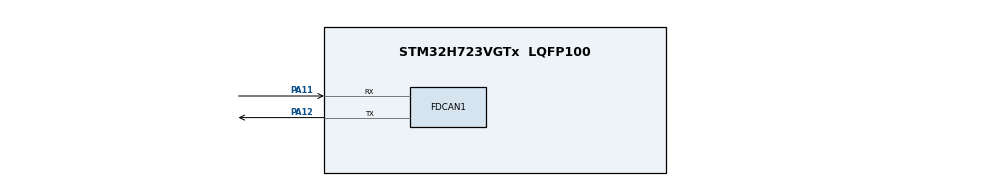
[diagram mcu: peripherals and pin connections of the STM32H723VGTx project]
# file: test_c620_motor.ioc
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CORTEX_M7.default_mode_Activation=1
FDCAN1.AutoRetransmission=ENABLE
FDCAN1.CalculateBaudRateNominal=1000000
FDCAN1.CalculateTimeBitNominal=1000
FDCAN1.CalculateTimeQuantumNominal=100.0
FDCAN1.DataPrescaler=10
FDCAN1.DataTimeSeg1=5
FDCAN1.DataTimeSeg2=4
FDCAN1.NominalPrescaler=10
FDCAN1.NominalTimeSeg1=5
FDCAN1.NominalTimeSeg2=4
FDCAN1.RxFifo1ElmtsNbr=16
FDCAN1.TxFifoQueueElmtsNbr=16
Mcu.Family=STM32H7
Mcu.Name=STM32H723VGTx
Mcu.Package=LQFP100
NVIC.FDCAN1_IT0_IRQn=true\:0\:0\:false\:false\:true\:true\:true\:true
NVIC.PriorityGroup=NVIC_PRIORITYGROUP_4
NVIC.TIM23_IRQn=true\:15\:0\:false\:false\:true\:false\:true\:true
NVIC.TimeBase=TIM23_IRQn
NVIC.TimeBaseIP=TIM23
PA11.Mode=FDCAN_Activate
PA11.Signal=FDCAN1_RX
PA12.Mode=FDCAN_Activate
PA12.Signal=FDCAN1_TX
PA13(JTMS/SWDIO).Mode=Serial_Wire
PA13(JTMS/SWDIO).Signal=DEBUG_JTMS-SWDIO
PA14(JTCK/SWCLK).Mode=Serial_Wire
PA14(JTCK/SWCLK).Signal=DEBUG_JTCK-SWCLK
PH0-OSC_IN.Mode=HSE-External-Oscillator
PH0-OSC_IN.Signal=RCC_OSC_IN
PH1-OSC_OUT.Mode=HSE-External-Oscillator
PH1-OSC_OUT.Signal=RCC_OSC_OUT
ProjectManager.HeapSize=0x200
ProjectManager.StackSize=0x400
ProjectManager.TargetToolchain=Makefile
RCC.ADCFreq_Value=48375000
RCC.APB1Freq_Value=24000000
RCC.APB2Freq_Value=24000000
RCC.APB3Freq_Value=24000000
RCC.APB4Freq_Value=24000000
RCC.CortexFreq_Value=24000000
RCC.DIVM1=2
RCC.DIVN1=25
RCC.DIVQ1=3
RCC.HCLKFreq_Value=24000000
RCC.HSE_VALUE=24000000
RCC.PLL2FRACN=0
RCC.PLL3FRACN=0
RCC.PLLFRACN=0
RCC.PLLSourceVirtual=RCC_PLLSOURCE_HSE
RCC.SYSCLKFreq_VALUE=24000000
RCC.SYSCLKSource=RCC_SYSCLKSOURCE_HSE
RCC.USBFreq_Value=100000000
VP_MEMORYMAP_VS_MEMORYMAP.Mode=CurAppReg
VP_SYS_VS_tim23.Mode=TIM23
board=custom

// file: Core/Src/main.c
/* USER CODE BEGIN Header */
/**
  ******************************************************************************
  * @file           : main.c
  * @brief          : Main program body
  ******************************************************************************
  * @attention
  *
  * Copyright (c) 2026 STMicroelectronics.
  * All rights reserved.
  *
  * This software is licensed under terms that can be found in the LICENSE file
  * in the root directory of this software component.
  * If no LICENSE file comes with this software, it is provided AS-IS.
  *
  ******************************************************************************
  */
/* USER CODE END Header */
#include "main.h"
#include "fdcan.h"
#include "gpio.h"

/* USER CODE BEGIN PV */

FDCAN_TxHeaderTypeDef tx_Header;
FDCAN_TxHeaderTypeDef hb_Header;
uint8_t  hb_data[8];
uint8_t  start_ok = 0;
uint8_t  tx_stat  = 0;
uint32_t fdcan_clk = 0;
uint32_t alive_cnt = 0;
uint32_t loop_cnt  = 0;
volatile uint32_t g_fault = 0;

void Txheader_Init(void)
{
        tx_Header.Identifier = 0x200 ;
        tx_Header.DataLength = FDCAN_DLC_BYTES_8 ;
        tx_Header.IdType = FDCAN_STANDARD_ID ;
        tx_Header.BitRateSwitch = FDCAN_BRS_OFF ;
        tx_Header.ErrorStateIndicator = FDCAN_ESI_ACTIVE ;
        tx_Header.FDFormat = FDCAN_CLASSIC_CAN ;
        tx_Header.MessageMarker = 0 ;
        tx_Header.TxEventFifoControl =FDCAN_NO_TX_EVENTS ;
        tx_Header.TxFrameType = FDCAN_DATA_FRAME ;

        hb_Header.Identifier = 0x700 ;
        hb_Header.DataLength = FDCAN_DLC_BYTES_8 ;
        hb_Header.IdType = FDCAN_STANDARD_ID ;
        hb_Header.BitRateSwitch = FDCAN_BRS_OFF ;
        hb_Header.ErrorStateIndicator = FDCAN_ESI_ACTIVE ;
        hb_Header.FDFormat = FDCAN_CLASSIC_CAN ;
        hb_Header.MessageMarker = 0 ;
        hb_Header.TxEventFifoControl = FDCAN_NO_TX_EVENTS ;
        hb_Header.TxFrameType = FDCAN_DATA_FRAME ;
}

uint8_t tx_data[8] ;
uint16_t current1 = 410 ;

void Current_Init(void)
{
    tx_data[0] = (current1 >> 8) & 0xff ;
    tx_data[1] = current1 & 0xff ;
    tx_data[2] = 0x00 ;
    tx_data[3] = 0x00 ;
    tx_data[4] = 0x00 ;
    tx_data[5] = 0x00 ;
    tx_data[6] = 0x00 ;
    tx_data[7] = 0x00 ;
}

/* USER CODE END PV */

void SystemClock_Config(void);
static void MPU_Config(void);

int main(void)
{

  /* MPU Configuration--------------------------------------------------------*/
  MPU_Config();

  /* MCU Configuration--------------------------------------------------------*/

  /* Reset of all peripherals, Initializes the Flash interface and the Systick. */
  HAL_Init();

  /* Configure the system clock */
  SystemClock_Config();

  /* Initialize all configured peripherals */
  MX_GPIO_Init();
  MX_FDCAN1_Init();
  /* USER CODE BEGIN 2 */

  Txheader_Init() ;
  Current_Init() ;

  if (HAL_FDCAN_Start(&hfdcan1) == HAL_OK)
  {
    start_ok = 1 ;
    fdcan_clk = HAL_RCCEx_GetPeriphCLKFreq(RCC_PERIPHCLK_FDCAN) ;
  }

  /* USER CODE END 2 */

  /* Infinite loop */
  /* USER CODE BEGIN WHILE */
  while (1)
  {
      tx_stat = HAL_FDCAN_AddMessageToTxFifoQ(&hfdcan1, &tx_Header, tx_data) ;

      if (loop_cnt >= 500)
      {
          loop_cnt = 0 ;
          hb_data[0] = (uint8_t)(alive_cnt & 0xFF) ; alive_cnt++ ;
          hb_data[1] = tx_stat ;
          hb_data[2] = start_ok ;
          hb_data[3] = (uint8_t)(fdcan_clk & 0xFF) ;
          hb_data[4] = (uint8_t)((fdcan_clk >> 8) & 0xFF) ;
          hb_data[5] = (uint8_t)((fdcan_clk >> 16) & 0xFF) ;
          hb_data[6] = (uint8_t)((fdcan_clk >> 24) & 0xFF) ;
          hb_data[7] = 0xA5 ;
          HAL_FDCAN_AddMessageToTxFifoQ(&hfdcan1, &hb_Header, hb_data) ;

          if (!start_ok)
          {
              if (HAL_FDCAN_Init(&hfdcan1) == HAL_OK)
              {
                  if (HAL_FDCAN_Start(&hfdcan1) == HAL_OK)
                  {
                      start_ok = 1 ;
                      fdcan_clk = HAL_RCCEx_GetPeriphCLKFreq(RCC_PERIPHCLK_FDCAN) ;
                  }
              }
          }
      }
      loop_cnt++ ;

      HAL_Delay(2) ;
    /* USER CODE END WHILE */

  }
}

void SystemClock_Config(void)
{
  RCC_OscInitTypeDef RCC_OscInitStruct = {0};
  RCC_ClkInitTypeDef RCC_ClkInitStruct = {0};

  /** Supply configuration update enable
  */
  HAL_PWREx_ConfigSupply(PWR_LDO_SUPPLY);

  /** Configure the main internal regulator output voltage
  */
  __HAL_PWR_VOLTAGESCALING_CONFIG(PWR_REGULATOR_VOLTAGE_SCALE3);

  while(!__HAL_PWR_GET_FLAG(PWR_FLAG_VOSRDY)) {}

  /** Initializes the RCC Oscillators according to the specified parameters
  * in the RCC_OscInitTypeDef structure.
  */
  RCC_OscInitStruct.OscillatorType = RCC_OSCILLATORTYPE_HSE;
  RCC_OscInitStruct.HSEState = RCC_HSE_ON;
  RCC_OscInitStruct.PLL.PLLState = RCC_PLL_ON;
  RCC_OscInitStruct.PLL.PLLSource = RCC_PLLSOURCE_HSE;
  RCC_OscInitStruct.PLL.PLLM = 2;
  RCC_OscInitStruct.PLL.PLLN = 25;
  RCC_OscInitStruct.PLL.PLLP = 2;
  RCC_OscInitStruct.PLL.PLLQ = 3;
  RCC_OscInitStruct.PLL.PLLR = 2;
  RCC_OscInitStruct.PLL.PLLRGE = RCC_PLL1VCIRANGE_3;
  RCC_OscInitStruct.PLL.PLLVCOSEL = RCC_PLL1VCOWIDE;
  RCC_OscInitStruct.PLL.PLLFRACN = 0;
  if (HAL_RCC_OscConfig(&RCC_OscInitStruct) != HAL_OK)
  {
    Error_Handler();
  }

  /** Initializes the CPU, AHB and APB buses clocks
  */
  RCC_ClkInitStruct.ClockType = RCC_CLOCKTYPE_HCLK|RCC_CLOCKTYPE_SYSCLK
                              |RCC_CLOCKTYPE_PCLK1|RCC_CLOCKTYPE_PCLK2
                              |RCC_CLOCKTYPE_D3PCLK1|RCC_CLOCKTYPE_D1PCLK1;
  RCC_ClkInitStruct.SYSCLKSource = RCC_SYSCLKSOURCE_HSE;
  RCC_ClkInitStruct.SYSCLKDivider = RCC_SYSCLK_DIV1;
  RCC_ClkInitStruct.AHBCLKDivider = RCC_HCLK_DIV1;
  RCC_ClkInitStruct.APB3CLKDivider = RCC_APB3_DIV1;
  RCC_ClkInitStruct.APB1CLKDivider = RCC_APB1_DIV1;
  RCC_ClkInitStruct.APB2CLKDivider = RCC_APB2_DIV1;
  RCC_ClkInitStruct.APB4CLKDivider = RCC_APB4_DIV1;

  if (HAL_RCC_ClockConfig(&RCC_ClkInitStruct, FLASH_LATENCY_0) != HAL_OK)
  {
    Error_Handler();
  }
}

 /* MPU Configuration */

void MPU_Config(void)
{
  MPU_Region_InitTypeDef MPU_InitStruct = {0};

  /* Disables the MPU */
  HAL_MPU_Disable();

  /** Initializes and configures the Region and the memory to be protected
  */
  MPU_InitStruct.Enable = MPU_REGION_ENABLE;
  MPU_InitStruct.Number = MPU_REGION_NUMBER0;
  MPU_InitStruct.BaseAddress = 0x0;
  MPU_InitStruct.Size = MPU_REGION_SIZE_4GB;
  MPU_InitStruct.SubRegionDisable = 0x87;
  MPU_InitStruct.TypeExtField = MPU_TEX_LEVEL0;
  MPU_InitStruct.AccessPermission = MPU_REGION_NO_ACCESS;
  MPU_InitStruct.DisableExec = MPU_INSTRUCTION_ACCESS_DISABLE;
  MPU_InitStruct.IsShareable = MPU_ACCESS_SHAREABLE;
  MPU_InitStruct.IsCacheable = MPU_ACCESS_NOT_CACHEABLE;
  MPU_InitStruct.IsBufferable = MPU_ACCESS_NOT_BUFFERABLE;

  HAL_MPU_ConfigRegion(&MPU_InitStruct);
  /* Enables the MPU */
  HAL_MPU_Enable(MPU_PRIVILEGED_DEFAULT);

}

void HAL_TIM_PeriodElapsedCallback(TIM_HandleTypeDef *htim)
{
  if (htim->Instance == TIM23)
  {
    HAL_IncTick();
  }
}

void Error_Handler(void)
{
  /* USER CODE BEGIN Error_Handler_Debug */
  /* User can add his own implementation to report the HAL error return state */
  g_fault++ ;
  return ;   /* non-fatal: keep firmware running so CAN diagnostics remain visible */
  /* USER CODE END Error_Handler_Debug */
}
